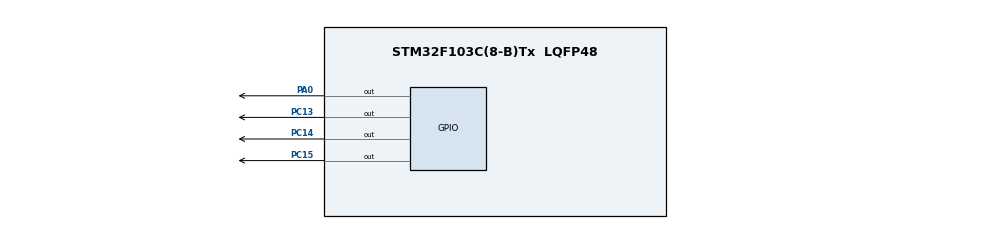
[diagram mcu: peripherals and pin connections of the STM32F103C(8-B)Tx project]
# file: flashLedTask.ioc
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FREERTOS.Tasks01=defaultTask,24,128,StartDefaultTask,Default,NULL,Dynamic,NULL,NULL;FlashGreenLed,24,128,FlashGreenLedTask,Default,NULL,Dynamic,NULL,NULL;FlashRedLed,32,128,FlashRedLedTask,Default,NULL,Dynamic,NULL,NULL
Mcu.Family=STM32F1
Mcu.Name=STM32F103C(8-B)Tx
Mcu.Package=LQFP48
NVIC.PriorityGroup=NVIC_PRIORITYGROUP_4
PA0-WKUP.Signal=GPIO_Output
PA13.Mode=Serial_Wire
PA13.Signal=SYS_JTMS-SWDIO
PA14.Mode=Serial_Wire
PA14.Signal=SYS_JTCK-SWCLK
PC13-TAMPER-RTC.Signal=GPIO_Output
PC14-OSC32_IN.Signal=GPIO_Output
PC15-OSC32_OUT.Signal=GPIO_Output
ProjectManager.HeapSize=0x200
ProjectManager.StackSize=0x400
ProjectManager.TargetToolchain=STM32CubeIDE
RCC.APB1Freq_Value=8000000
RCC.APB2Freq_Value=8000000
VP_FREERTOS_VS_CMSIS_V2.Mode=CMSIS_V2
board=custom

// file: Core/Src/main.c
/* USER CODE BEGIN Header */
/**
  ******************************************************************************
  * @file           : main.c
  * @brief          : Main program body
  ******************************************************************************
  * @attention
  *
  * Copyright (c) 2024 STMicroelectronics.
  * All rights reserved.
  *
  * This software is licensed under terms that can be found in the LICENSE file
  * in the root directory of this software component.
  * If no LICENSE file comes with this software, it is provided AS-IS.
  *
  ******************************************************************************
  */
/* USER CODE END Header */
#include "main.h"
#include "cmsis_os.h"

/* Definitions for defaultTask */
osThreadId_t defaultTaskHandle;
const osThreadAttr_t defaultTask_attributes = {
  .name = "defaultTask",
  .stack_size = 128 * 4,
  .priority = (osPriority_t) osPriorityNormal,
};
/* Definitions for FlashGreenLed */
osThreadId_t FlashGreenLedHandle;
const osThreadAttr_t FlashGreenLed_attributes = {
  .name = "FlashGreenLed",
  .stack_size = 128 * 4,
  .priority = (osPriority_t) osPriorityNormal,
};
/* Definitions for FlashRedLed */
osThreadId_t FlashRedLedHandle;
const osThreadAttr_t FlashRedLed_attributes = {
  .name = "FlashRedLed",
  .stack_size = 128 * 4,
  .priority = (osPriority_t) osPriorityAboveNormal,
};
/* USER CODE BEGIN PV */
volatile uint8_t greenLedState = 0;   // 0: Off, 1: On
volatile uint8_t redLedState = 0;     // 0: Off, 1: On
volatile uint8_t blueLedState = 0;    // 0: Off, 1: On (Blue)
volatile uint8_t orangeLedState = 0;  // 0: Off, 1: On (Orange)

/* USER CODE END PV */

void SystemClock_Config(void);
static void MX_GPIO_Init(void);
void StartDefaultTask(void *argument);
void FlashGreenLedTask(void *argument);
void FlashRedLedTask(void *argument);

/* USER CODE BEGIN PFP */
void SWV_Print(const char *msg) {
    while (*msg) {
        ITM_SendChar(*msg++);  // Kirim karakter satu per satu melalui SWV
    }
}
/* USER CODE END PFP */

int main(void)
{

  /* MCU Configuration--------------------------------------------------------*/

  /* Reset of all peripherals, Initializes the Flash interface and the Systick. */
  HAL_Init();

  /* Configure the system clock */
  SystemClock_Config();

  /* Initialize all configured peripherals */
  MX_GPIO_Init();

  /* Init scheduler */
  osKernelInitialize();

  /* Create the thread(s) */
  /* creation of defaultTask */
  defaultTaskHandle = osThreadNew(StartDefaultTask, NULL, &defaultTask_attributes);

  /* creation of FlashGreenLed */
  FlashGreenLedHandle = osThreadNew(FlashGreenLedTask, NULL, &FlashGreenLed_attributes);

  /* creation of FlashRedLed */
  FlashRedLedHandle = osThreadNew(FlashRedLedTask, NULL, &FlashRedLed_attributes);

  /* Start scheduler */
  osKernelStart();

  /* We should never get here as control is now taken by the scheduler */

  /* Infinite loop */
  while (1)
  {

  }
}

void SystemClock_Config(void)
{
  RCC_OscInitTypeDef RCC_OscInitStruct = {0};
  RCC_ClkInitTypeDef RCC_ClkInitStruct = {0};

  /** Initializes the RCC Oscillators according to the specified parameters
  * in the RCC_OscInitTypeDef structure.
  */
  RCC_OscInitStruct.OscillatorType = RCC_OSCILLATORTYPE_HSI;
  RCC_OscInitStruct.HSIState = RCC_HSI_ON;
  RCC_OscInitStruct.HSICalibrationValue = RCC_HSICALIBRATION_DEFAULT;
  RCC_OscInitStruct.PLL.PLLState = RCC_PLL_NONE;
  if (HAL_RCC_OscConfig(&RCC_OscInitStruct) != HAL_OK)
  {
    Error_Handler();
  }

  /** Initializes the CPU, AHB and APB buses clocks
  */
  RCC_ClkInitStruct.ClockType = RCC_CLOCKTYPE_HCLK|RCC_CLOCKTYPE_SYSCLK
                              |RCC_CLOCKTYPE_PCLK1|RCC_CLOCKTYPE_PCLK2;
  RCC_ClkInitStruct.SYSCLKSource = RCC_SYSCLKSOURCE_HSI;
  RCC_ClkInitStruct.AHBCLKDivider = RCC_SYSCLK_DIV1;
  RCC_ClkInitStruct.APB1CLKDivider = RCC_HCLK_DIV1;
  RCC_ClkInitStruct.APB2CLKDivider = RCC_HCLK_DIV1;

  if (HAL_RCC_ClockConfig(&RCC_ClkInitStruct, FLASH_LATENCY_0) != HAL_OK)
  {
    Error_Handler();
  }
}

static void MX_GPIO_Init(void)
{
  GPIO_InitTypeDef GPIO_InitStruct = {0};

  /* GPIO Ports Clock Enable */
  __HAL_RCC_GPIOC_CLK_ENABLE();
  __HAL_RCC_GPIOA_CLK_ENABLE();

  /*Configure GPIO pin Output Level */
  HAL_GPIO_WritePin(GPIOC, GPIO_PIN_13|GPIO_PIN_14|GPIO_PIN_15, GPIO_PIN_RESET);

  /*Configure GPIO pin Output Level */
  HAL_GPIO_WritePin(GPIOA, GPIO_PIN_0, GPIO_PIN_RESET);

  /*Configure GPIO pins : PC13 PC14 PC15 */
  GPIO_InitStruct.Pin = GPIO_PIN_13|GPIO_PIN_14|GPIO_PIN_15;
  GPIO_InitStruct.Mode = GPIO_MODE_OUTPUT_PP;
  GPIO_InitStruct.Pull = GPIO_NOPULL;
  GPIO_InitStruct.Speed = GPIO_SPEED_FREQ_LOW;
  HAL_GPIO_Init(GPIOC, &GPIO_InitStruct);

  /*Configure GPIO pin : PA0 */
  GPIO_InitStruct.Pin = GPIO_PIN_0;
  GPIO_InitStruct.Mode = GPIO_MODE_OUTPUT_PP;
  GPIO_InitStruct.Pull = GPIO_NOPULL;
  GPIO_InitStruct.Speed = GPIO_SPEED_FREQ_LOW;
  HAL_GPIO_Init(GPIOA, &GPIO_InitStruct);

}

void StartDefaultTask(void *argument)
{
  for(;;)
  {
    osDelay(1);
  }
}

void FlashGreenLedTask(void *argument) {
    for (;;) {
        HAL_GPIO_WritePin(GPIOC, GPIO_PIN_13, GPIO_PIN_SET);  // Blue LED On (Task active)
        blueLedState = 1;
        SWV_Print("Blue LED On (Task Active)\n");

        SWV_Print("Green LED Task Started\n");

        // Simulasi eksekusi: Toggle LED Hijau selama 4 detik (20 Hz)
        for (int i = 0; i < 80; i++) {
            HAL_GPIO_TogglePin(GPIOC, GPIO_PIN_14);  // Green LED Toggle
            greenLedState = !greenLedState;  // Update state
            SWV_Print(greenLedState ? "Green LED On\n" : "Green LED Off\n");
            osDelay(50);  // Delay 50ms
        }

        HAL_GPIO_WritePin(GPIOC, GPIO_PIN_14, GPIO_PIN_RESET);  // Green LED Off
        greenLedState = 0;
        SWV_Print("Green LED Off\n");

        HAL_GPIO_WritePin(GPIOC, GPIO_PIN_13, GPIO_PIN_RESET);  // Blue LED Off
        blueLedState = 0;
        SWV_Print("Blue LED Off (Task Suspended)\n");

        osDelay(6000);  // Suspend 6 detik
    }
}

void FlashRedLedTask(void *argument) {
    for (;;) {
        HAL_GPIO_WritePin(GPIOA, GPIO_PIN_0, GPIO_PIN_SET);  // Orange LED On (Task active)
        orangeLedState = 1;
        SWV_Print("Orange LED On (Task Active)\n");

        SWV_Print("Red LED Task Started\n");

        // Simulasi eksekusi: Toggle LED Merah selama 0.5 detik (20 Hz)
        for (int i = 0; i < 10; i++) {
            HAL_GPIO_TogglePin(GPIOC, GPIO_PIN_15);  // Red LED Toggle
            redLedState = !redLedState;  // Update state
            SWV_Print(redLedState ? "Red LED On\n" : "Red LED Off\n");
            osDelay(50);  // Delay 50ms
        }

        HAL_GPIO_WritePin(GPIOC, GPIO_PIN_15, GPIO_PIN_RESET);  // Red LED Off
        redLedState = 0;
        SWV_Print("Red LED Off\n");

        HAL_GPIO_WritePin(GPIOA, GPIO_PIN_0, GPIO_PIN_RESET);  // Orange LED Off
        orangeLedState = 0;
        SWV_Print("Orange LED Off (Task Suspended)\n");

        osDelay(1500);  // Suspend 1.5 detik
    }
}

void Error_Handler(void)
{
  __disable_irq();
  while (1)
  {
  }
}
